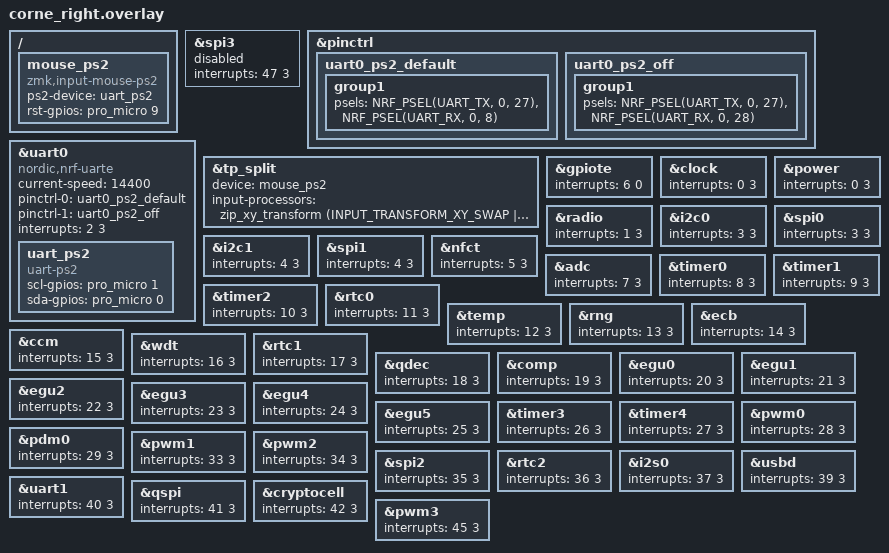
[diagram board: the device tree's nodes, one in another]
/*
 * Right half: corne + IBM/Lenovo TrackPoint over PS/2.
 *
 * Wiring (nice!nano v2, "pro micro" pin numbering):
 *
 *   PS/2 DATA  ->  D0  (P0.08)   must be the UART RX pin
 *   PS/2 CLK   ->  D1  (P0.06)
 *   TP RST     ->  D9  (P1.06)   power-on-reset, omit if you built the RC reset circuit
 *   VCC / GND  ->  3.3V / GND
 *
 * The driver implements the PS/2 protocol on top of the nRF52 UART hardware:
 * it receives with UART (hence DATA on the RX pin) and bit-bangs writes on
 * DATA + CLK, parking the UART on unconnected pins while it does so.
 */

#include "trackpoint.dtsi"

/*
 * The stock corne shield drives WS2812 underglow from SPI3 MOSI on P0.06,
 * which is the D1 pin we need for the PS/2 clock. SPI3 is enabled by that
 * shield overlay even with RGB off, so hand the pin back here.
 */
&spi3 {
    status = "disabled";
};

&pinctrl {
    /*
     * Receive state: UART RX on the PS/2 data pin. UART TX is unused by the
     * PS/2 protocol but still has to be assigned, so park it on P0.27, which
     * the nice!nano does not break out.
     */
    uart0_ps2_default: uart0_ps2_default {
        group1 {
            psels = <NRF_PSEL(UART_TX, 0, 27)>,
                    <NRF_PSEL(UART_RX, 0, 8)>;
        };
    };

    /*
     * "Sleep" state: both UART pins parked on unexposed pins. The driver
     * switches to this (via PM_DEVICE) to release the data pin whenever it
     * needs to drive DATA/CLK as GPIOs to send a command to the trackpoint.
     */
    uart0_ps2_off: uart0_ps2_off {
        group1 {
            psels = <NRF_PSEL(UART_TX, 0, 27)>,
                    <NRF_PSEL(UART_RX, 0, 28)>;
        };
    };
};

&uart0 {
    status = "okay";
    compatible = "nordic,nrf-uarte";

    /*
     * PS/2 devices clock at 10-16.7kHz; trackpoints are usually ~15kHz
     * (~67us per bit). 14400 baud (69.4us) is the closest zephyr baud rate
     * and works with every trackpoint the community has tried. If yours
     * never initialises, try 9600 or 19200.
     */
    current-speed = <14400>;

    pinctrl-0 = <&uart0_ps2_default>;
    pinctrl-1 = <&uart0_ps2_off>;
    pinctrl-names = "default", "sleep";

    uart_ps2: uart_ps2 {
        status = "okay";
        compatible = "uart-ps2";
        scl-gpios = <&pro_micro 1 GPIO_ACTIVE_HIGH>;
        sda-gpios = <&pro_micro 0 GPIO_ACTIVE_HIGH>;
    };
};

/ {
    mouse_ps2: mouse_ps2 {
        status = "okay";
        compatible = "zmk,input-mouse-ps2";
        ps2-device = <&uart_ps2>;

        /*
         * Most trackpoints need a power-on-reset pulse. Drop this property
         * if you wired the resistor/capacitor reset circuit instead.
         */
        rst-gpios = <&pro_micro 9 GPIO_ACTIVE_HIGH>;

        /*
         * Optional trackpoint tuning, all adjustable at runtime with the
         * &mms behavior as well:
         *
         * sampling-rate = <100>;      // 10/20/40/60/80/100/200
         * tp-sensitivity = <128>;     // 0-255, higher = faster
         * tp-neg-inertia = <6>;       // 0-255
         * tp-val6-upper-speed = <97>; // 0-255
         */
    };
};

&tp_split {
    device = <&mouse_ps2>;

    /*
     * The trackpoint is mounted rotated 90 degrees, so swap the axes and
     * invert one of them. Fixing it here means the corrected events are what
     * gets sent to the central half.
     *
     * If the pointer moves at right angles to your finger, the swap is
     * missing; if it moves backwards along one axis, flip which invert is
     * used. The four rotations are:
     *
     *   0deg   : (no processor needed)
     *   90deg  : XY_SWAP | Y_INVERT      <- current
     *   180deg : X_INVERT | Y_INVERT
     *   270deg : XY_SWAP | X_INVERT
     */
    input-processors = <&zip_xy_transform (INPUT_TRANSFORM_XY_SWAP | INPUT_TRANSFORM_Y_INVERT)>;
};

/*
 * Interrupt priority overrides.
 *
 * A PS/2 bit has to be serviced within 30-50us, and bluetooth interrupts
 * regularly run longer than that. The PS/2 driver's Kconfig already demotes
 * the BT controller priorities (BT_CTLR_LLL_PRIO 1, ULL_HIGH/ULL_LOW 2); the
 * devicetree half of that is done here: GPIOTE is promoted to the highest
 * priority and every other peripheral is demoted to 3 so it cannot delay the
 * bluetooth interrupts that were just demoted.
 *
 * Generated for the nRF52840 with
 * kb_zmk_ps2_mouse_trackpoint_driver/scripts/gen_interrupt_priority_overrides.py
 */

&gpiote { interrupts = <6 0>; };

&clock     { interrupts = <0 3>; };
&power     { interrupts = <0 3>; };
&radio     { interrupts = <1 3>; };
&uart0     { interrupts = <2 3>; };
&i2c0      { interrupts = <3 3>; };
&spi0      { interrupts = <3 3>; };
&i2c1      { interrupts = <4 3>; };
&spi1      { interrupts = <4 3>; };
&nfct      { interrupts = <5 3>; };
&adc       { interrupts = <7 3>; };
&timer0    { interrupts = <8 3>; };
&timer1    { interrupts = <9 3>; };
&timer2    { interrupts = <10 3>; };
&rtc0      { interrupts = <11 3>; };
&temp      { interrupts = <12 3>; };
&rng       { interrupts = <13 3>; };
&ecb       { interrupts = <14 3>; };
&ccm       { interrupts = <15 3>; };
&wdt       { interrupts = <16 3>; };
&rtc1      { interrupts = <17 3>; };
&qdec      { interrupts = <18 3>; };
&comp      { interrupts = <19 3>; };
&egu0      { interrupts = <20 3>; };
&egu1      { interrupts = <21 3>; };
&egu2      { interrupts = <22 3>; };
&egu3      { interrupts = <23 3>; };
&egu4      { interrupts = <24 3>; };
&egu5      { interrupts = <25 3>; };
&timer3    { interrupts = <26 3>; };
&timer4    { interrupts = <27 3>; };
&pwm0      { interrupts = <28 3>; };
&pdm0      { interrupts = <29 3>; };
&pwm1      { interrupts = <33 3>; };
&pwm2      { interrupts = <34 3>; };
&spi2      { interrupts = <35 3>; };
&rtc2      { interrupts = <36 3>; };
&i2s0      { interrupts = <37 3>; };
&usbd      { interrupts = <39 3>; };
&uart1     { interrupts = <40 3>; };
&qspi      { interrupts = <41 3>; };
&cryptocell { interrupts = <42 3>; };
&pwm3      { interrupts = <45 3>; };
&spi3      { interrupts = <47 3>; };
